# MCU_NAVSS0_INTR0_CFG register map
Vendor: Texas Instruments
Peripheral module from a debugger description file (folder am65x).
Registers are 32-bit, read-only, reset values left out (the file's numbers can be read two ways) unless marked. A register's access mark holds for its fields unless they carry their own. Offsets are as the file gives them; lines under a group give offsets from that group; [hi:lo] are bit positions; {n}, {i} and the like mark numbered series; 'fields as' and 'values as' point back to an identical list; <NAME> marks a mode.

## MCU_NAVSS0_INTR0_CFG
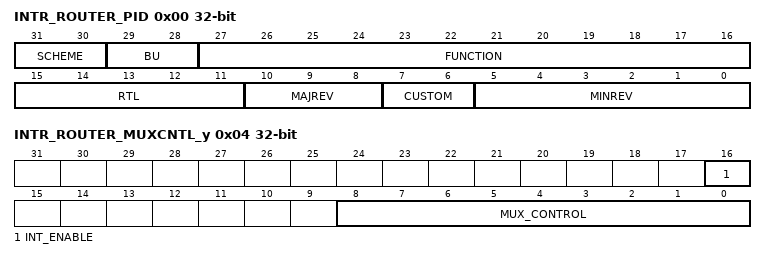
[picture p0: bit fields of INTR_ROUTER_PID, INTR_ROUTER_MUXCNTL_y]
0x00 INTR_ROUTER_PID — Identification register
  [31:30] SCHEME — PID scheme
  [29:28] BU
  [27:16] FUNCTION
  [15:11] RTL — RTL version 10h - NAVSS0 Fh - MCU_NAVSS0
  [10:8] MAJREV — major version
  [7:6] CUSTOM — custom id
  [5:0] MINREV — minor version
0x04 INTR_ROUTER_MUXCNTL_y rw — Interrupt mux control register Offset = 4h + (y * 4); where y = 0h to 1FFh for NAVSS0 Offset = 4h + (y * 4); where y = 0h to 3Fh for MCU_NAVSS0
  [16] INT_ENABLE — Interrupt output enable for interrupt y
  [8:0] MUX_CONTROL — Mux control for interrupt y Avoid programming the mux control when input interrutps are enabled via INT_ENABLE.
